# CTRL_MODULE_CORE_PAD register map
Vendor: Texas Instruments
Registers are 32-bit, access per field, reset 0x10F010F unless marked. A register's access mark holds for its fields unless they carry their own. Offsets are as the file gives them; [hi:lo] are bit positions; lines under a group give offsets from that group; {n}, {i} and the like mark numbered series; 'fields as' and 'values as' point back to an identical list.

## CTRL_MODULE_CORE_PAD (part 7 of 7)
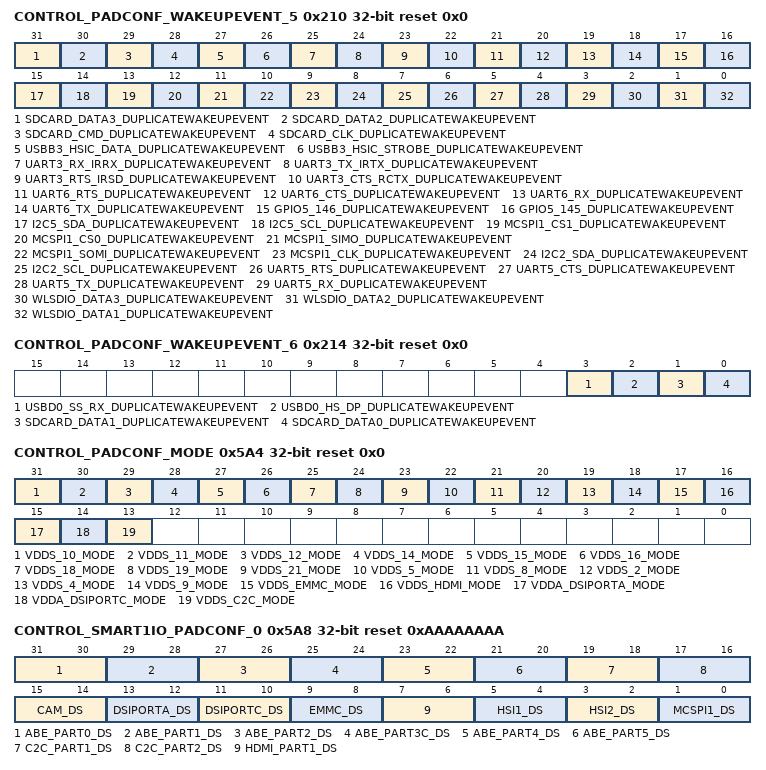
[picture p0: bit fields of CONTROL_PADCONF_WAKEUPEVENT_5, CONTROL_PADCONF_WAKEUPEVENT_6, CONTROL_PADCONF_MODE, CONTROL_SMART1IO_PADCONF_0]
0x210 CONTROL_PADCONF_WAKEUPEVENT_5 ro reset 0x0 — Access conditions. Read: unrestricted, Write: unrestricted
  [all] fields
    1=WakeUp (A wakeup event occurred); 0=No wakeup event occurred
  [31] SDCARD_DATA3_DUPLICATEWAKEUPEVENT — Wake-up event status latched in the IO for pad sdcard_data3
  [30] SDCARD_DATA2_DUPLICATEWAKEUPEVENT — Wake-up event status latched in the IO for pad sdcard_data2
  [29] SDCARD_CMD_DUPLICATEWAKEUPEVENT — Wake-up event status latched in the IO for pad sdcard_cmd
  [28] SDCARD_CLK_DUPLICATEWAKEUPEVENT — Wake-up event status latched in the IO for pad sdcard_clk
  [27] USBB3_HSIC_DATA_DUPLICATEWAKEUPEVENT — Wake-up event status latched in the IO for pad usbb3_hsic_data
  [26] USBB3_HSIC_STROBE_DUPLICATEWAKEUPEVENT — Wake-up event status latched in the IO for pad usbb3_hsic_strobe
  [25] UART3_RX_IRRX_DUPLICATEWAKEUPEVENT — Wake-up event status latched in the IO for pad uart3_rx_irrx
  [24] UART3_TX_IRTX_DUPLICATEWAKEUPEVENT — Wake-up event status latched in the IO for pad uart3_tx_irtx
  [23] UART3_RTS_IRSD_DUPLICATEWAKEUPEVENT — Wake-up event status latched in the IO for pad uart3_rts_irsd
  [22] UART3_CTS_RCTX_DUPLICATEWAKEUPEVENT — Wake-up event status latched in the IO for pad uart3_cts_rctx
  [21] UART6_RTS_DUPLICATEWAKEUPEVENT — Wake-up event status latched in the IO for pad uart6_rts
  [20] UART6_CTS_DUPLICATEWAKEUPEVENT — Wake-up event status latched in the IO for pad uart6_cts
  [19] UART6_RX_DUPLICATEWAKEUPEVENT — Wake-up event status latched in the IO for pad uart6_rx
  [18] UART6_TX_DUPLICATEWAKEUPEVENT — Wake-up event status latched in the IO for pad uart6_tx
  [17] GPIO5_146_DUPLICATEWAKEUPEVENT — Wake-up event status latched in the IO for pad gpio5_146
  [16] GPIO5_145_DUPLICATEWAKEUPEVENT — Wake-up event status latched in the IO for pad gpio5_145
  [15] I2C5_SDA_DUPLICATEWAKEUPEVENT — Wake-up event status latched in the IO for pad i2c5_sda
  [14] I2C5_SCL_DUPLICATEWAKEUPEVENT — Wake-up event status latched in the IO for pad i2c5_scl
  [13] MCSPI1_CS1_DUPLICATEWAKEUPEVENT — Wake-up event status latched in the IO for pad mcspi1_cs1
  [12] MCSPI1_CS0_DUPLICATEWAKEUPEVENT — Wake-up event status latched in the IO for pad mcspi1_cs0
  [11] MCSPI1_SIMO_DUPLICATEWAKEUPEVENT — Wake-up event status latched in the IO for pad mcspi1_simo
  [10] MCSPI1_SOMI_DUPLICATEWAKEUPEVENT — Wake-up event status latched in the IO for pad mcspi1_somi
  [9] MCSPI1_CLK_DUPLICATEWAKEUPEVENT — Wake-up event status latched in the IO for pad mcspi1_clk
  [8] I2C2_SDA_DUPLICATEWAKEUPEVENT — Wake-up event status latched in the IO for pad i2c2_sda
  [7] I2C2_SCL_DUPLICATEWAKEUPEVENT — Wake-up event status latched in the IO for pad i2c2_scl
  [6] UART5_RTS_DUPLICATEWAKEUPEVENT — Wake-up event status latched in the IO for pad uart5_rts
  [5] UART5_CTS_DUPLICATEWAKEUPEVENT — Wake-up event status latched in the IO for pad uart5_cts
  [4] UART5_TX_DUPLICATEWAKEUPEVENT — Wake-up event status latched in the IO for pad uart5_tx
  [3] UART5_RX_DUPLICATEWAKEUPEVENT — Wake-up event status latched in the IO for pad uart5_rx
  [2] WLSDIO_DATA3_DUPLICATEWAKEUPEVENT — Wake-up event status latched in the IO for pad wlsdio_data3
  [1] WLSDIO_DATA2_DUPLICATEWAKEUPEVENT — Wake-up event status latched in the IO for pad wlsdio_data2
  [0] WLSDIO_DATA1_DUPLICATEWAKEUPEVENT — Wake-up event status latched in the IO for pad wlsdio_data1
0x214 CONTROL_PADCONF_WAKEUPEVENT_6 ro reset 0x0 — Access conditions. Read: unrestricted, Write: unrestricted
  [all] fields
    values as the fields of CONTROL_PADCONF_WAKEUPEVENT_5
  [3] USBD0_SS_RX_DUPLICATEWAKEUPEVENT — Wake-up event status latched in the IO for pad usbd0_ss_rx
  [2] USBD0_HS_DP_DUPLICATEWAKEUPEVENT — Wake-up event status latched in the IO for pad usbd0_hs_dp
  [1] SDCARD_DATA1_DUPLICATEWAKEUPEVENT — Wake-up event status latched in the IO for pad sdcard_data1
  [0] SDCARD_DATA0_DUPLICATEWAKEUPEVENT — Wake-up event status latched in the IO for pad sdcard_data0
0x5A4 CONTROL_PADCONF_MODE reset 0x0 — PAD Voltage Mode control Access conditions. Read: unrestricted, Write: unrestricted
  [all] fields
    0=1V8 (VDDS = 1.8V); 1=1V2 (VDDS = 1.2V)
  [31] VDDS_10_MODE rw — PAD Voltage level control for vdds_10_mode
  [30] VDDS_11_MODE rw — PAD Voltage level control for vdds_11_mode
  [29] VDDS_12_MODE rw — PAD Voltage level control for vdds_12_mode
  [28] VDDS_14_MODE rw — PAD Voltage level control for vdds_14_mode
  [27] VDDS_15_MODE rw — PAD Voltage level control for vdds_15_mode
  [26] VDDS_16_MODE rw — PAD Voltage level control for vdds_16_mode
  [25] VDDS_18_MODE rw — PAD Voltage level control for vdds_18_mode
  [24] VDDS_19_MODE rw — PAD Voltage level control for vdds_19_mode
  [23] VDDS_21_MODE rw — PAD Voltage level control for vdds_21_mode
  [22] VDDS_5_MODE rw — PAD Voltage level control for vdds_5_mode
  [21] VDDS_8_MODE rw — PAD Voltage level control for vdds_8_mode
  [20] VDDS_2_MODE rw — PAD Voltage level control for vdds_8_mode
  [19] VDDS_4_MODE rw — PAD Voltage level control for vdds_4_mode
  [18] VDDS_9_MODE rw — PAD Voltage level control for vdds_9_mode
  [17] VDDS_EMMC_MODE rw — PAD Voltage level control for vdds_emmc_mode
  [16] VDDS_HDMI_MODE rw — PAD Voltage level control for vdds_hdmi_mode
  [15] VDDA_DSIPORTA_MODE rw — PAD Voltage level control for vdda_dsiporta_mode
  [14] VDDA_DSIPORTC_MODE rw — PAD Voltage level control for vdda_dsiporta_mode
  [13] VDDS_C2C_MODE rw — PAD Voltage level control for vdds_c2c_mode
0x5A8 CONTROL_SMART1IO_PADCONF_0 rw reset 0xAAAAAAAA — SMART1 IO control 0 Access conditions. Read: unrestricted, Write: unrestricted
  [all] fields
    0=ds0 (120 ohm); 1=ds1 (60 ohm); 3=ds3 (30 ohm); 2=ds2 (45 ohm)
  [31:30] ABE_PART0_DS — DS control for abe part0
  [29:28] ABE_PART1_DS — DS control for abe part1
  [27:26] ABE_PART2_DS — DS control for abe part2
  [25:24] ABE_PART3C_DS — DS control for abe part3 clock
  [23:22] ABE_PART4_DS — DS control for abe part4
  [21:20] ABE_PART5_DS — DS control for abe part5
  [19:18] C2C_PART1_DS — DS control for c2c part1
  [17:16] C2C_PART2_DS — DS control for c2c part2
  [15:14] CAM_DS — DS control for cam
  [13:12] DSIPORTA_DS — DS control for iporta
  [11:10] DSIPORTC_DS — DS control for iportc
  [9:8] EMMC_DS — DS control for emmc
  [7:6] HDMI_PART1_DS — DS control for hdmi part1
  [5:4] HSI1_DS — DS control for hsi1 part1
  [3:2] HSI2_DS — DS control for hsi2 part1
  [1:0] MCSPI1_DS — DS control for mcspi1
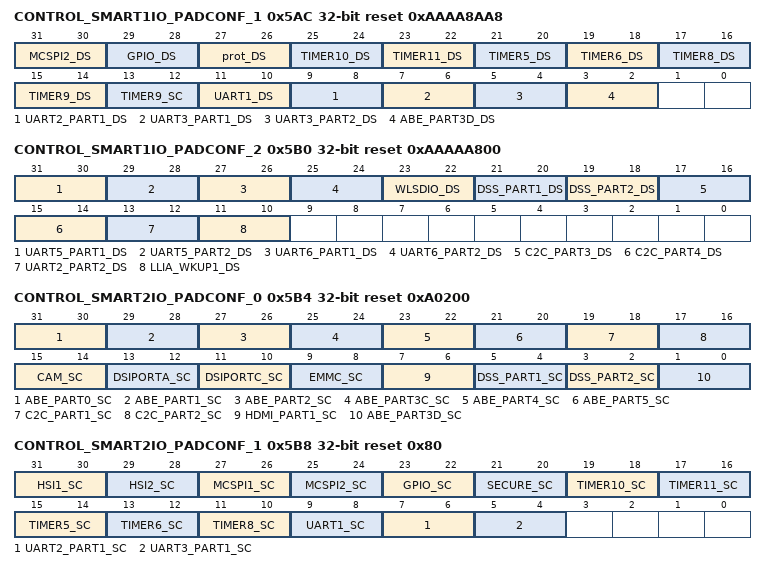
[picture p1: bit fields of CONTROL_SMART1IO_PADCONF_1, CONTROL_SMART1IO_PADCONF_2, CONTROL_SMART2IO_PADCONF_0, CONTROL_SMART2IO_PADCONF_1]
0x5AC CONTROL_SMART1IO_PADCONF_1 reset 0xAAAA8AA8 — SMART1 IO control 1 Access conditions. Read: unrestricted, Write: unrestricted
  [all] fields
    values as the fields of CONTROL_SMART1IO_PADCONF_0
  [31:30] MCSPI2_DS rw — DS control for mcspi2
  [29:28] GPIO_DS rw — DS control for gpio
  [27:26] prot_DS rw — DS control for prot
  [25:24] TIMER10_DS rw — DS control for timer10
  [23:22] TIMER11_DS rw — DS control for timer11
  [21:20] TIMER5_DS rw — DS control for timer5
  [19:18] TIMER6_DS rw — DS control for timer6
  [17:16] TIMER8_DS rw — DS control for timer8
  [15:14] TIMER9_DS rw — DS control for timer9
  [13:12] TIMER9_SC rw — DS control for timer9 sc
  [11:10] UART1_DS rw — DS control for uart1
  [9:8] UART2_PART1_DS rw — DS control for uart2 part1
  [7:6] UART3_PART1_DS rw — DS control for uart3 part1
  [5:4] UART3_PART2_DS rw — DS control for uart3 part2
  [3:2] ABE_PART3D_DS rw — DS control for abe part3 clock
0x5B0 CONTROL_SMART1IO_PADCONF_2 reset 0xAAAAA800 — SMART1 IO control 2 Access conditions. Read: unrestricted, Write: unrestricted
  [all] fields
    values as the fields of CONTROL_SMART1IO_PADCONF_0
  [31:30] UART5_PART1_DS rw — DS control for uart5 part1
  [29:28] UART5_PART2_DS rw — DS control for uart5 part2
  [27:26] UART6_PART1_DS rw — DS control for uart6 part1
  [25:24] UART6_PART2_DS rw — DS control for uart6 part2
  [23:22] WLSDIO_DS rw — DS control for wlsdio
  [21:20] DSS_PART1_DS rw — DS control for dss part1
  [19:18] DSS_PART2_DS rw — DS control for dss part1
  [17:16] C2C_PART3_DS rw — DS control for c2c part3
  [15:14] C2C_PART4_DS rw — DS control for c2c part4
  [13:12] UART2_PART2_DS rw — DS control for uart2 part2
  [11:10] LLIA_WKUP1_DS rw — DS control for llia wakeup1
0x5B4 CONTROL_SMART2IO_PADCONF_0 rw reset 0xA0200 — SMART2 IO control 0 Access conditions. Read: unrestricted, Write: unrestricted
  [31:30] ABE_PART0_SC — slew rate control for abe part0
    0=sc0 (slow); 1=sc1 (medium); 3=sc3 (not_applicable); 2=sc2 (fast)
  [29:28] ABE_PART1_SC — slew rate control for abe part1
    values as ABE_PART0_SC
  [27:26] ABE_PART2_SC — slew rate control for abe part2
    values as ABE_PART0_SC
  [25:24] ABE_PART3C_SC — slew rate control for abe part3
    values as ABE_PART0_SC
  [23:22] ABE_PART4_SC — slew rate control for abe part4
    values as ABE_PART0_SC
  [21:20] ABE_PART5_SC — slew rate control for abe part5
    values as ABE_PART0_SC
  [19:18] C2C_PART1_SC — slew rate control for c2c part1
    values as ABE_PART0_SC
  [17:16] C2C_PART2_SC — slew rate control for c2c part2
    values as ABE_PART0_SC
  [15:14] CAM_SC — slew rate control for cam
    values as ABE_PART0_SC
  [13:12] DSIPORTA_SC — slew rate control for dsiporta
    values as ABE_PART0_SC
  [11:10] DSIPORTC_SC — slew rate control for dsiportc
    values as ABE_PART0_SC
  [9:8] EMMC_SC — slew rate control for emmc
    values as ABE_PART0_SC
  [7:6] HDMI_PART1_SC — slew rate control for hdmi part1
    values as ABE_PART0_SC
  [5:4] DSS_PART1_SC — slew rate control for dss part1
    values as ABE_PART0_SC
  [3:2] DSS_PART2_SC — slew rate control for dss part2
    values as ABE_PART0_SC
  [1:0] ABE_PART3D_SC
0x5B8 CONTROL_SMART2IO_PADCONF_1 reset 0x80 — SMART2 IO control 1 Access conditions. Read: unrestricted, Write: unrestricted
  [all] fields
    values as CONTROL_SMART2IO_PADCONF_0.ABE_PART0_SC
  [31:30] HSI1_SC rw — slew rate control for hsi1 part1
  [29:28] HSI2_SC rw — slew rate control for hsi2 part1
  [27:26] MCSPI1_SC rw — slew rate control for mcspi1
  [25:24] MCSPI2_SC rw — slew rate control for mcspi2
  [23:22] GPIO_SC rw — slew rate control for gpio
  [21:20] SECURE_SC rw — slew rate control for secure
  [19:18] TIMER10_SC rw — slew rate control for timer10
  [17:16] TIMER11_SC rw — slew rate control for timer11
  [15:14] TIMER5_SC rw — slew rate control for timer5
  [13:12] TIMER6_SC rw — slew rate control for timer6
  [11:10] TIMER8_SC rw — slew rate control for timer8
  [9:8] UART1_SC rw — slew rate control for uart1
  [7:6] UART2_PART1_SC rw — slew rate control for uart2 part1
  [5:4] UART3_PART1_SC rw — slew rate control for uart3 part1
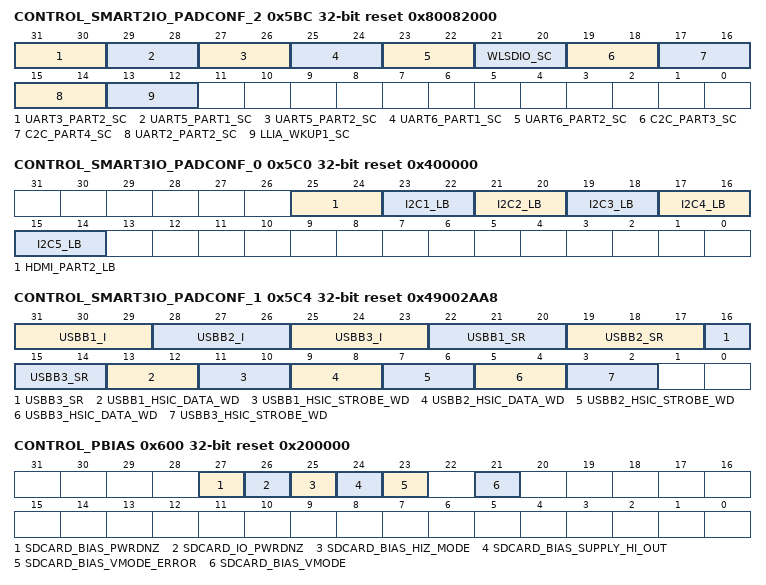
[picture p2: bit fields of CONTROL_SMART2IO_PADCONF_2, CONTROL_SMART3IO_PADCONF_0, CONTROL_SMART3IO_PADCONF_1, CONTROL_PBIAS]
0x5BC CONTROL_SMART2IO_PADCONF_2 reset 0x80082000 — SMART2 IO control 2 Access conditions. Read: unrestricted, Write: unrestricted
  [all] fields
    values as CONTROL_SMART2IO_PADCONF_0.ABE_PART0_SC
  [31:30] UART3_PART2_SC rw — slew rate control for uart3 part2
  [29:28] UART5_PART1_SC rw — slew rate control for uart5 part1
  [27:26] UART5_PART2_SC rw — slew rate control for uart5 part2
  [25:24] UART6_PART1_SC rw — slew rate control for uart6 part1
  [23:22] UART6_PART2_SC rw — slew rate control for uart6 part2
  [21:20] WLSDIO_SC rw — slew rate control for wlsdio
  [19:18] C2C_PART3_SC rw — slew rate control for c2c part3
  [17:16] C2C_PART4_SC rw — slew rate control for c2c part4
  [15:14] UART2_PART2_SC rw — slew rate control for uart2 part2
  [13:12] LLIA_WKUP1_SC rw — slew rate control for llia wakeup
0x5C0 CONTROL_SMART3IO_PADCONF_0 reset 0x400000 — SMART3 IO control 0. samrt reflex Access conditions. Read: unrestricted, Write: unrestricted
  [all] fields
    0=lb0 (Fast mode(5-15pf),High-Speed mode(5-12pf)); 1=lb1 (Fast mode(15-50pf),High-Speed mode(12-25pf)); 3=lb3 (Fast mode(N/A),High-Speed mode(50-80pf)); 2=lb2 (Fast mode(50-150pf),High-Speed mode(25-50pf))
  [25:24] HDMI_PART2_LB rw — lb (internal pull-up resistors for both Fast and High-Speed modes) for control for hdmi_part2
  [25-2n:24-2n] I2C{n}_LB rw (n=1..5) — lb (internal pull-up resistors for both Fast and High-Speed modes) for control for i2c{n}
0x5C4 CONTROL_SMART3IO_PADCONF_1 reset 0x49002AA8 — SMART3 IO control 1 Access conditions. Read: unrestricted, Write: unrestricted
  [31:29] USBB1_I rw — usbb1 HSIC Impedence control i3:i2:i0
    0=i2 (i0)
  [28:26] USBB2_I rw — usbb2 HSIC Impedence control i3:i2:i0
    0=i2 (i0)
  [25:23] USBB3_I rw — usbb3 HSIC Impedence control i3:i2:i0
    0=i2 (i0)
  [22:20] USBB1_SR rw — usbb1 HSIC Slew Rate control sr2:sr1:sr0
    0=sr1 (sr0)
  [19:17] USBB2_SR rw — usbb2 HSIC Slew Rate control sr2:sr1:sr0
    0=sr1 (sr0)
  [16:14] USBB3_SR rw — usbb3 HSIC Slew Rate control sr2:sr1:sr0
    0=sr1 (sr0)
  [13:12] USBB1_HSIC_DATA_WD rw — usbb1 HSIC DATA Weak Driver control i2:i0
    0=i0
  [11:10] USBB1_HSIC_STROBE_WD rw — usbb1 HSIC STROBE Weak Driver control i2:i0
    0=i0
  [9:8] USBB2_HSIC_DATA_WD rw — usbb2 HSIC DATA Weak Driver control i2:i0
    0=i0
  [7:6] USBB2_HSIC_STROBE_WD rw — usbb2 HSIC STROBE Weak Driver control i2:i0
    0=i0
  [5:4] USBB3_HSIC_DATA_WD rw — usbb3 HSIC DATA Weak Driver control i2:i0
    0=i0
  [3:2] USBB3_HSIC_STROBE_WD rw — usbb3 HSIC STROBE Weak Driver control i2:i0
    0=i0
0x600 CONTROL_PBIAS reset 0x200000 — PBIAS control Access conditions. Read: unrestricted, Write: unrestricted
  [27] SDCARD_BIAS_PWRDNZ rw — PWRDNZ control for SDCARD PBIAS cell
    0=Enable (This signal is used to protect SDCARD PBIAS cell when SDCARD_VDDS is not stable); 1=Disable (SW keep this bit to 1'b1 after SDCARD_VDDS stabilizing)
  [26] SDCARD_IO_PWRDNZ rw — PWRDNZ control for SDCARD I/O cell
    0=Enable (This signal is used to protect SDCARD IOs when SDCARD_VDDS is not stable); 1=Disable (SW keep this bit to 1'b1 after SDCARD_VDDS stabilizing)
  [25] SDCARD_BIAS_HIZ_MODE rw — HIZ_MODE from SDCARD PBIAS
    0=Enable (PBIAS in normal operation mode); 1=Disable (PBIAS output is in high impedence state)
  [24] SDCARD_BIAS_SUPPLY_HI_OUT ro — SUPPLY_HI_OUT from SDCARD PBIAS
    1=3V (SDCARD_VDDS = 3V); 0=1V8 (SDCARD_VDDS = 1.8V)
  [23] SDCARD_BIAS_VMODE_ERROR ro — VMODE ERROR from SDCARD PBIAS
    1=VMODE_ERROR1 (VMODE level is not same as SUPPLY_HI_OUT); 0=VMODE_ERROR0 (VMODE level is same as SUPPLY_HI_OUT)
  [21] SDCARD_BIAS_VMODE rw — VMODE control to SDCARD PBIAS. Not applicable when the pad muxing selects SDCARD. When SDCARD is selected by the pad muxing, PBIAS VMODE is directly controlled by the MMCHS IP via bit MMCHS.MMCHS_AC12[19] V1V8_SIGEN
    0=1V8 (SDCARD_VDDS = 1.8V); 1=3V (SDCARD_VDDS = 3V)
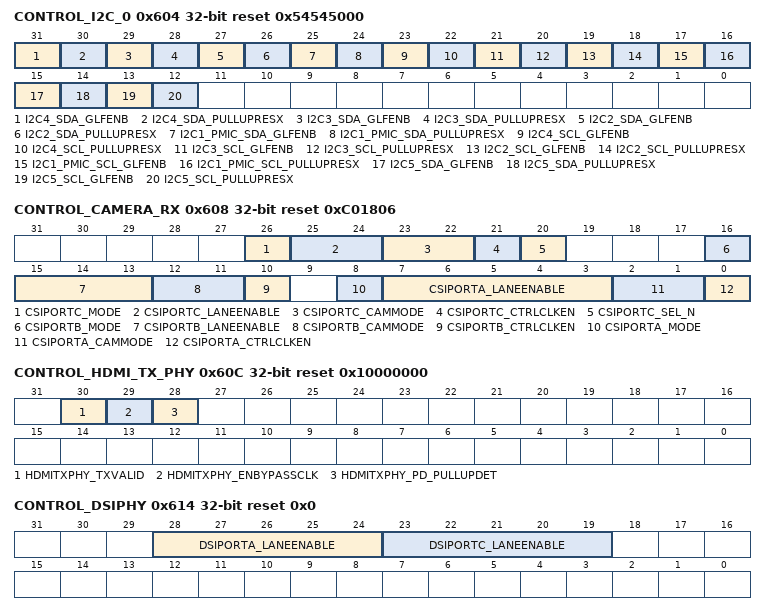
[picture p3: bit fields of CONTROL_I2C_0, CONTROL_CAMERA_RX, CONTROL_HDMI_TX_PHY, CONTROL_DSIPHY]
0x604 CONTROL_I2C_0 reset 0x54545000 — I2C pads control 0 Access conditions. Read: unrestricted, Write: unrestricted
  [31] I2C4_SDA_GLFENB rw — Active_high glitch free operation enable pin for i2c4 receiver
    0=Disable i2c4 glitch free operation; 1=Enable i2c4 glitch free operation
  [30] I2C4_SDA_PULLUPRESX rw — Active_low internal pull_up resistor enabled for i2c4
    0=Enable Internal Pull up resistor; 1=Disable Internal Pull up resisitor
  [29] I2C3_SDA_GLFENB rw — Active_high glitch free operation enable pin for i2c3 receiver
    values as I2C4_SDA_GLFENB
  [28] I2C3_SDA_PULLUPRESX rw — Active_low internal pull_up resistor enabled for i2c3
    values as I2C4_SDA_PULLUPRESX
  [27] I2C2_SDA_GLFENB rw — Active_high glitch free operation enable pin for i2c2 receiver
    values as I2C4_SDA_GLFENB
  [26] I2C2_SDA_PULLUPRESX rw — Active_low internal pull_up resistor enabled for i2c2
    values as I2C4_SDA_PULLUPRESX
  [25] I2C1_PMIC_SDA_GLFENB rw — Active_high glitch free operation enable pin for i2c1_pmic receiver
    values as I2C4_SDA_GLFENB
  [24] I2C1_PMIC_SDA_PULLUPRESX rw — Active_low internal pull_up resistor enabled for i2c1_pmic
    values as I2C4_SDA_PULLUPRESX
  [23] I2C4_SCL_GLFENB rw — Active_high glitch free operation enable pin for i2c4 receiver
    values as I2C4_SDA_GLFENB
  [22] I2C4_SCL_PULLUPRESX rw — Active_low internal pull_up resistor enabled for i2c4
    values as I2C4_SDA_PULLUPRESX
  [21] I2C3_SCL_GLFENB rw — Active_high glitch free operation enable pin for i2c3 receiver
    values as I2C4_SDA_GLFENB
  [20] I2C3_SCL_PULLUPRESX rw — Active_low internal pull_up resistor enabled for i2c3
    values as I2C4_SDA_PULLUPRESX
  [19] I2C2_SCL_GLFENB rw — Active_high glitch free operation enable pin for i2c2 receiver
    values as I2C4_SDA_GLFENB
  [18] I2C2_SCL_PULLUPRESX rw — Active_low internal pull_up resistor enabled for i2c2
    values as I2C4_SDA_PULLUPRESX
  [17] I2C1_PMIC_SCL_GLFENB rw — Active_high glitch free operation enable pin for i2c1_pmic receiver
    values as I2C4_SDA_GLFENB
  [16] I2C1_PMIC_SCL_PULLUPRESX rw — Active_low internal pull_up resistor enabled for i2c1_pmic
    values as I2C4_SDA_PULLUPRESX
  [15] I2C5_SDA_GLFENB rw — Active_high glitch free operation enable pin for i2c5 receiver
    0=Disable i2c5 glitch free operation; 1=Enable i2c5 glitch free operation
  [14] I2C5_SDA_PULLUPRESX rw — Active_low internal pull_up resistor enabled for i2c5
    values as I2C4_SDA_PULLUPRESX
  [13] I2C5_SCL_GLFENB rw — Active_high glitch free operation enable pin for i2c5 receiver
    values as I2C5_SDA_GLFENB
  [12] I2C5_SCL_PULLUPRESX rw — Active_low internal pull_up resistor enabled for i2c5
    values as I2C4_SDA_PULLUPRESX
0x608 CONTROL_CAMERA_RX reset 0xC01806 — CAMERA RX control Access conditions. Read: unrestricted, Write: unrestricted
  [26] CSIPORTC_MODE rw — portc camera MODE
  [25:24] CSIPORTC_LANEENABLE rw — portc camera Lane Enable
    0=Disable (Lane module disabled); 1=Enable (Lane module enabled)
  [23:22] CSIPORTC_CAMMODE rw — portc camera CAMMODE control
    0=DPHY (DPHY mode); 1=CCP2_Data_Strobe (Data/Strobe Transmission for mat); 3=GPI (GPI mode); 2=CCP2_Data_Clock (Data/Clock Transmission for mat)
  [21] CSIPORTC_CTRLCLKEN rw — portc cameraclock enable control. This is the internal PHY CTRLCLK driven from CSI_PHY_CTRL_FCLK.
    0=Disable for CTRLCLK; 1=Enable (Active high enable for CTRLCLK)
  [20] CSIPORTC_SEL_N rw — select port
    0=csiportc (select portc); 1=portb (select portb)
  [16] CSIPORTB_MODE rw — portb camera MODE
  [15:13] CSIPORTB_LANEENABLE rw — portb camera Lane Enable
    values as CSIPORTC_LANEENABLE
  [12:11] CSIPORTB_CAMMODE rw — portb camera CAMMODE control
    values as CSIPORTC_CAMMODE
  [10] CSIPORTB_CTRLCLKEN rw — portb camera clock enable control. This is the internal PHY CTRLCLK driven from CSI_PHY_CTRL_FCLK.
    values as CSIPORTC_CTRLCLKEN
  [8] CSIPORTA_MODE rw — porta camera MODE
  [7:3] CSIPORTA_LANEENABLE rw — porta camera Lane Enable
    values as CSIPORTC_LANEENABLE
  [2:1] CSIPORTA_CAMMODE rw — porta camera CAMMODE control
    values as CSIPORTC_CAMMODE
  [0] CSIPORTA_CTRLCLKEN rw — porta cameraclock enable control. This is the internal PHY CTRLCLK driven from CSI_PHY_CTRL_FCLK.
    values as CSIPORTC_CTRLCLKEN
0x60C CONTROL_HDMI_TX_PHY reset 0x10000000 — HDMI TX PHY control Access conditions. Read: unrestricted, Write: unrestricted
  [30] HDMITXPHY_TXVALID rw, [29] HDMITXPHY_ENBYPASSCLK rw, [28] HDMITXPHY_PD_PULLUPDET rw
0x614 CONTROL_DSIPHY reset 0x0 — DSIPHY control Access conditions. Read: unrestricted, Write: unrestricted
  [28:24] DSIPORTA_LANEENABLE rw
    values as CONTROL_CAMERA_RX.CSIPORTC_LANEENABLE
  [23:19] DSIPORTC_LANEENABLE rw
    0=Enable (Pull down enabled); 1=Disable (Pull down disabled)
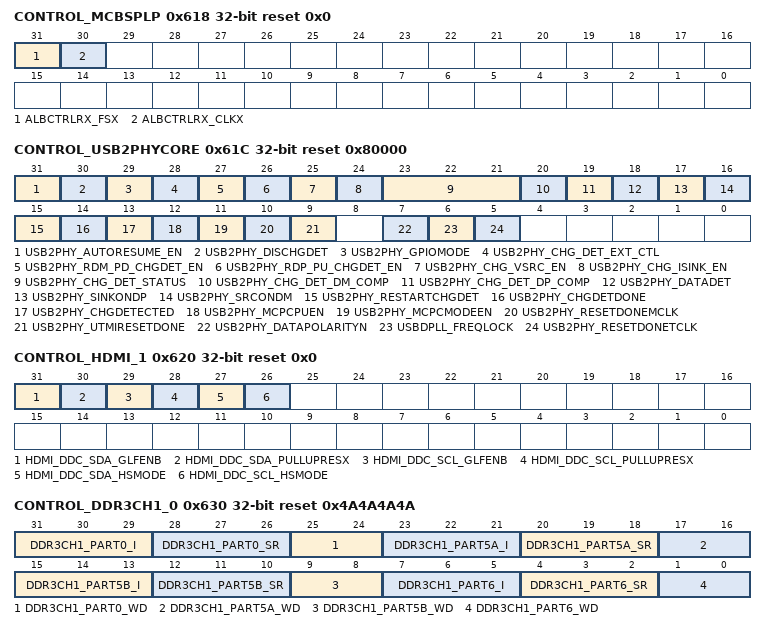
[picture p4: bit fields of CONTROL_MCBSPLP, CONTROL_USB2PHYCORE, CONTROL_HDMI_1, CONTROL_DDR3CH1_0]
0x618 CONTROL_MCBSPLP reset 0x0 — McBSPLP control Access conditions. Read: unrestricted, Write: unrestricted
  [31] ALBCTRLRX_FSX rw — Analog loop_back control for FSX
    0=PIFSR (PIFSR is used); 1=PIFSX (PIFSX is used instead of PIFSR 4pin mode)
  [30] ALBCTRLRX_CLKX rw — Analog loop_back control for CLKX
    0=PICLKR (PICLKR is used); 1=PICLKX (PICLKX is used instead of PICLKR 4pin mode)
0x61C CONTROL_USB2PHYCORE reset 0x80000 — USB2PHYCORE control Access conditions. Read: unrestricted, Write: unrestricted
  [31] USB2PHY_AUTORESUME_EN rw — Auto resume enable
    0=disable autoresume; 1=enable autoresume
  [30] USB2PHY_DISCHGDET rw — Disable charger detect
    0=Enable (charger detect function enabled); 1=Disable (charger detect function disabled)
  [29] USB2PHY_GPIOMODE rw — GPIO mode
    0=Disable (USB mode enabled); 1=Enable (GPIO mode enabled)
  [28] USB2PHY_CHG_DET_EXT_CTL rw — Charge detect external control
    0=Enable (charger detect internal state machine used); 1=Disable (charge detect statemachine is bypassed)
  [27] USB2PHY_RDM_PD_CHGDET_EN rw — DM Pull down control
    0=Disable (PD disabled); 1=Enable (PD enabled)
  [26] USB2PHY_RDP_PU_CHGDET_EN rw — DP Pull up control
    0=Disable (PU disabled); 1=Enable (PU enabled)
  [25] USB2PHY_CHG_VSRC_EN rw — VSRC enable on DP line-Host charger case
    0=disable VSRC drive on DP; 1=Enable (drives VSRC 600mV on DP line)
  [24] USB2PHY_CHG_ISINK_EN rw — ISINK enable on DM line-Host charger case
    0=disable the isink on DM; 1=enables the ISINK (100uA) on DM line
  [23:21] USB2PHY_CHG_DET_STATUS ro — Status of charger detection
    3=USB2PHY_CHG_DET_STATUS_3_r (Unknown error); 4=USB2PHY_CHG_DET_STATUS_4_r (Dedicated charger); 2=USB2PHY_CHG_DET_STATUS_2_r (PS/2); 0=USB2PHY_CHG_DET_STATUS_0_r (Wait state); 6=USB2PHY_CHG_DET_STATUS_6_r (PC); 1=USB2PHY_CHG_DET_STATUS_1_r (No contact); 7=USB2PHY_CHG_DET_STATUS_7_r (Interrupt); 5=USB2PHY_CHG_DET_STATUS_5_r (HOST charger)
  [20] USB2PHY_CHG_DET_DM_COMP ro — Output of the comparator on DM during the resistor host detect protocol
    1=Above (DM line is above 0.75V to 0.95V); 0=Below (DM line is below 0.75V to 0.95V)
  [19] USB2PHY_CHG_DET_DP_COMP ro — Output of the comparator on DP during the resistor host detect protocol
    1=Above (DP line is above 0.75V to 0.95V); 0=Below (DP line is below 0.75V to 0.95V)
  [18] USB2PHY_DATADET ro — Output of the charger detect comparator
    1=Above (DM line is above 0.25V to 0.4V); 0=Below (DM line is below 0.25V to 0.4V)
  [17] USB2PHY_SINKONDP rw — When '1' current sink is connected to DP instead of DM
    0=Default value; 1=enables the ISINK on DP instead of DM
  [16] USB2PHY_SRCONDM rw — When '1' voltage source is connected to DP instead of DM
    0=Default value; 1=enable the VSRC on DM instead of DP
  [15] USB2PHY_RESTARTCHGDET rw — restartchgdet = '1' for 1 msec cause the CD_START to reset
    0=Default value; 1=RESTART (a high pulse of 1 msec causes the charger detect to restart on negative edge of restartchgdet)
  [14] USB2PHY_CHGDETDONE ro — Status indicates that charger detection protocol is over
    1=completed (charger detection protocol is over); 0=not_completed (charger detection protocol is not over)
  [13] USB2PHY_CHGDETECTED ro — Output of the charger detection protocol
    1=detected (charger detected); 0=not_detected (charger not detected)
  [12] USB2PHY_MCPCPUEN rw — MCPC Pull up enable
    0=disable the MCPC pull up; 1=enable the 4.7K to10K pull up on receive line DP when datapolarityn is 0 and DM when datapolarityn is 1
  [11] USB2PHY_MCPCMODEEN rw — MCPC Mode enable
    0=disable MCPC mode; 1=enable MCPC mode
  [10] USB2PHY_RESETDONEMCLK ro — OCP reset status
    1=OUT_OF_RESET (OCP domain is out of reset); 0=IN_RESET (OCP domain is in reset)
  [9] USB2PHY_UTMIRESETDONE ro — UTMI FSM reset status
    1=UTMI_FSM_OUT_OF_RESET (UTMI FSMs are out of reset); 0=UTMI_FSM_INRESET (UTMI FSMs are in reset)
  [7] USB2PHY_DATAPOLARITYN rw — Data polarity
    0=Normal (DP functionality is on DP and DM funcationality is on DM); 1=INVERTED (DP functionality is on DM and DM functionality is on DP)
  [6] USBDPLL_FREQLOCK ro — Status from USB DPLL
  [5] USB2PHY_RESETDONETCLK ro — resetdonetclk status from USB2PHY
0x620 CONTROL_HDMI_1 reset 0x0 — HDMI pads control 1 Access conditions. Read: unrestricted, Write: unrestricted
  [31] HDMI_DDC_SDA_GLFENB rw — Active_high glitch free operation enable pin for hdmi_ddc_sda receiver
    0=Disable hdmi_ddc_sda glitch free operation; 1=Enable hdmi_ddc_sda glitch free operation
  [30] HDMI_DDC_SDA_PULLUPRESX rw — Active_low internal pull_up resistor enabled for hdmi_ddc_sda
    values as CONTROL_I2C_0.I2C4_SDA_PULLUPRESX
  [29] HDMI_DDC_SCL_GLFENB rw — Active_high glitch free operation enable pin for hdmi_ddc_scl receiver
    0=Disable hdmi_ddc_sc glitch free operation; 1=Enable hdmi_ddc_sc glitch free operation
  [28] HDMI_DDC_SCL_PULLUPRESX rw — Active_low internal pull_up resistor enabled for hdmi_ddc_scl
    values as CONTROL_I2C_0.I2C4_SDA_PULLUPRESX
  [27] HDMI_DDC_SDA_HSMODE rw — Active-high selection for I2C High-Speed mode
    0=Disable (I2C Standard/Fast mode); 1=Enable I2C High speed mode
  [26] HDMI_DDC_SCL_HSMODE rw — Active-high selection for I2C High-Speed mode
    values as HDMI_DDC_SDA_HSMODE
0x630 CONTROL_DDR3CH1_0 rw reset 0x4A4A4A4A — DDR3CH1 control For more information about pad group assignment and signal group parameter controls, see , Signal Integrity Parameter Controls Overview, and . Access conditions. Read: unrestricted, Write: unrestricted
  [31:29] DDR3CH1_PART0_I — Group 0 Impedence control i3:i2:i0
    6=0p73Rext (for Drv11); 1=1p33Rext (for Drv6); 7=0p67Rext (Drv12); 0=1p6Rext (for Drv5); 2=1p14Rext (for Drv7); 4=0p88Rext (for Drv9); 5=0p8Rext (for Drv10); 3=Rext (for Drv8)
  [28:26] DDR3CH1_PART0_SR — Group 0 Slew Rate control sr2:sr1:sr0
    0=Fastest (Turn_on time 125ps for Drv8); 1=Slow (Turn_on time 500ps for Drv8); 3=Slowest (Turn_on time 750ps for Drv8); 2=Fast (Turn_on time 325ps for Drv8)
  [25:24] DDR3CH1_PART0_WD — Group 0 Weak driver control wd1:wd0
    0=None (Pull logic disabled); 1=PU (pull up); 3=Keeper (Maintain the previous output value); 2=PD (pull down)
  [23:21] DDR3CH1_PART5A_I — Group 5 Impedence control i3:i2:i0
    values as DDR3CH1_PART0_I
  [20:18] DDR3CH1_PART5A_SR — Group 5 Slew Rate control sr2:sr1:sr0
    values as DDR3CH1_PART0_SR
  [17:16] DDR3CH1_PART5A_WD — Group 5 Weak driver control wd1:wd0
    values as DDR3CH1_PART0_WD
  [15:13] DDR3CH1_PART5B_I — Group 6 Impedence control i3:i2:i0
    values as DDR3CH1_PART0_I
  [12:10] DDR3CH1_PART5B_SR — Group 6 Slew Rate control sr2:sr1:sr0
    values as DDR3CH1_PART0_SR
  [9:8] DDR3CH1_PART5B_WD — Group 6 Weak driver control wd1:wd0
    values as DDR3CH1_PART0_WD
  [7:5] DDR3CH1_PART6_I — Group 6 Impedence control i3:i2:i0
    values as DDR3CH1_PART0_I
  [4:2] DDR3CH1_PART6_SR — Group 6 Slew Rate control sr2:sr1:sr0
    values as DDR3CH1_PART0_SR
  [1:0] DDR3CH1_PART6_WD — Group 6 Weak driver control wd1:wd0
    values as DDR3CH1_PART0_WD
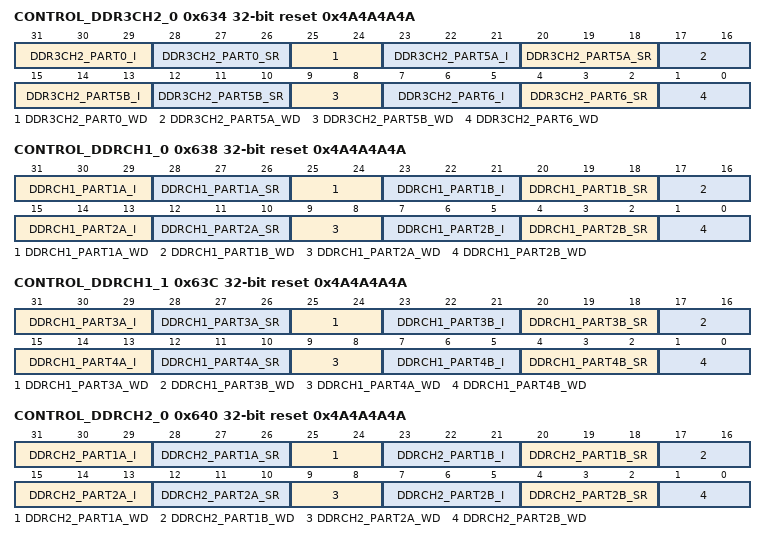
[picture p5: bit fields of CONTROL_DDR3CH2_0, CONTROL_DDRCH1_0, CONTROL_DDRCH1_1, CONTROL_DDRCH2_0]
0x634 CONTROL_DDR3CH2_0 rw reset 0x4A4A4A4A — DDR3CH2 control For more information about pad group assignment and signal group parameter controls, see , Signal Integrity Parameter Controls Overview, and . Access conditions. Read: unrestricted, Write: unrestricted
  [31:29] DDR3CH2_PART0_I — Group 0 Impedence control i3:i2:i0
    values as CONTROL_DDR3CH1_0.DDR3CH1_PART0_I
  [28:26] DDR3CH2_PART0_SR — Group 0 Slew Rate control sr2:sr1:sr0
    values as CONTROL_DDR3CH1_0.DDR3CH1_PART0_SR
  [25:24] DDR3CH2_PART0_WD — Group 0 Weak driver control wd1:wd0
    values as CONTROL_DDR3CH1_0.DDR3CH1_PART0_WD
  [23:21] DDR3CH2_PART5A_I — Group 5 Impedence control i3:i2:i0
    values as CONTROL_DDR3CH1_0.DDR3CH1_PART0_I
  [20:18] DDR3CH2_PART5A_SR — Group 5 Slew Rate control sr2:sr1:sr0
    values as CONTROL_DDR3CH1_0.DDR3CH1_PART0_SR
  [17:16] DDR3CH2_PART5A_WD — Group 5 Weak driver control wd1:wd0
    values as CONTROL_DDR3CH1_0.DDR3CH1_PART0_WD
  [15:13] DDR3CH2_PART5B_I — Group 6 Impedence control i3:i2:i0
    values as CONTROL_DDR3CH1_0.DDR3CH1_PART0_I
  [12:10] DDR3CH2_PART5B_SR — Group 6 Slew Rate control sr2:sr1:sr0
    values as CONTROL_DDR3CH1_0.DDR3CH1_PART0_SR
  [9:8] DDR3CH2_PART5B_WD — Group 6 Weak driver control wd1:wd0
    values as CONTROL_DDR3CH1_0.DDR3CH1_PART0_WD
  [7:5] DDR3CH2_PART6_I — Group 6 Impedence control i3:i2:i0
    values as CONTROL_DDR3CH1_0.DDR3CH1_PART0_I
  [4:2] DDR3CH2_PART6_SR — Group 6 Slew Rate control sr2:sr1:sr0
    values as CONTROL_DDR3CH1_0.DDR3CH1_PART0_SR
  [1:0] DDR3CH2_PART6_WD — Group 6 Weak driver control wd1:wd0
    values as CONTROL_DDR3CH1_0.DDR3CH1_PART0_WD
0x638 CONTROL_DDRCH1_0 rw reset 0x4A4A4A4A — DDRCH1 control 0 For more information about pad group assignment and signal group parameter controls, see , Signal Integrity Parameter Controls Overview, and . Access conditions. Read: unrestricted, Write: unrestricted
  [31:29] DDRCH1_PART1A_I — Group 1a Impedence control i3:i2:i0
    values as CONTROL_DDR3CH1_0.DDR3CH1_PART0_I
  [28:26] DDRCH1_PART1A_SR — Group 1a Slew Rate control sr2:sr1:sr0
    values as CONTROL_DDR3CH1_0.DDR3CH1_PART0_SR
  [25:24] DDRCH1_PART1A_WD — Group 1a Weak driver control wd1:wd0
    values as CONTROL_DDR3CH1_0.DDR3CH1_PART0_WD
  [23:21] DDRCH1_PART1B_I — Group 1b Impedence control i3:i2:i0
    values as CONTROL_DDR3CH1_0.DDR3CH1_PART0_I
  [20:18] DDRCH1_PART1B_SR — Group 1b Slew Rate control sr2:sr1:sr0
    values as CONTROL_DDR3CH1_0.DDR3CH1_PART0_SR
  [17:16] DDRCH1_PART1B_WD — Group 1b Weak driver control wd1:wd0
    values as CONTROL_DDR3CH1_0.DDR3CH1_PART0_WD
  [15:13] DDRCH1_PART2A_I — Group 2a Impedence control i3:i2:i0
    values as CONTROL_DDR3CH1_0.DDR3CH1_PART0_I
  [12:10] DDRCH1_PART2A_SR — Group 2a Slew Rate control sr2:sr1:sr0
    values as CONTROL_DDR3CH1_0.DDR3CH1_PART0_SR
  [9:8] DDRCH1_PART2A_WD — Group 2a Weak driver control wd1:wd0
    values as CONTROL_DDR3CH1_0.DDR3CH1_PART0_WD
  [7:5] DDRCH1_PART2B_I — Group 2b Impedence control i3:i2:i0
    values as CONTROL_DDR3CH1_0.DDR3CH1_PART0_I
  [4:2] DDRCH1_PART2B_SR — Group 2b Slew Rate control sr2:sr1:sr0
    values as CONTROL_DDR3CH1_0.DDR3CH1_PART0_SR
  [1:0] DDRCH1_PART2B_WD — Group 2b Weak driver control wd1:wd0
    values as CONTROL_DDR3CH1_0.DDR3CH1_PART0_WD
0x63C CONTROL_DDRCH1_1 rw reset 0x4A4A4A4A — DDRCH1 control 1 For more information about pad group assignment and signal group parameter controls, see , Signal Integrity Parameter Controls Overview, and . Access conditions. Read: unrestricted, Write: unrestricted
  [31:29] DDRCH1_PART3A_I — Group 3a Impedence control i3:i2:i0
    values as CONTROL_DDR3CH1_0.DDR3CH1_PART0_I
  [28:26] DDRCH1_PART3A_SR — Group 3a Slew Rate control sr2:sr1:sr0
    values as CONTROL_DDR3CH1_0.DDR3CH1_PART0_SR
  [25:24] DDRCH1_PART3A_WD — Group 3a Weak driver control wd1:wd0
    values as CONTROL_DDR3CH1_0.DDR3CH1_PART0_WD
  [23:21] DDRCH1_PART3B_I — Group 3b Impedence control i3:i2:i0
    values as CONTROL_DDR3CH1_0.DDR3CH1_PART0_I
  [20:18] DDRCH1_PART3B_SR — Group 3b Slew Rate control sr2:sr1:sr0
    values as CONTROL_DDR3CH1_0.DDR3CH1_PART0_SR
  [17:16] DDRCH1_PART3B_WD — Group 3b Weak driver control wd1:wd0
    values as CONTROL_DDR3CH1_0.DDR3CH1_PART0_WD
  [15:13] DDRCH1_PART4A_I — Group 4a Impedence control i3:i2:i0
    values as CONTROL_DDR3CH1_0.DDR3CH1_PART0_I
  [12:10] DDRCH1_PART4A_SR — Group 4a Slew Rate control sr2:sr1:sr0
    values as CONTROL_DDR3CH1_0.DDR3CH1_PART0_SR
  [9:8] DDRCH1_PART4A_WD — Group 4a Weak driver control wd1:wd0
    values as CONTROL_DDR3CH1_0.DDR3CH1_PART0_WD
  [7:5] DDRCH1_PART4B_I — Group 4b Impedence control i3:i2:i0
    values as CONTROL_DDR3CH1_0.DDR3CH1_PART0_I
  [4:2] DDRCH1_PART4B_SR — Group 4b Slew Rate control sr2:sr1:sr0
    values as CONTROL_DDR3CH1_0.DDR3CH1_PART0_SR
  [1:0] DDRCH1_PART4B_WD — Group 4b Weak driver control wd1:wd0
    values as CONTROL_DDR3CH1_0.DDR3CH1_PART0_WD
0x640 CONTROL_DDRCH2_0 rw reset 0x4A4A4A4A — DDRCH2 control 0 For more information about pad group assignment and signal group parameter controls, see , Signal Integrity Parameter Controls Overview, and . Access conditions. Read: unrestricted, Write: unrestricted
  [31:29] DDRCH2_PART1A_I — Group 1a Impedence control i3:i2:i0
    values as CONTROL_DDR3CH1_0.DDR3CH1_PART0_I
  [28:26] DDRCH2_PART1A_SR — Group 1a Slew Rate control sr2:sr1:sr0
    values as CONTROL_DDR3CH1_0.DDR3CH1_PART0_SR
  [25:24] DDRCH2_PART1A_WD — Group 1a Weak driver control wd1:wd0
    values as CONTROL_DDR3CH1_0.DDR3CH1_PART0_WD
  [23:21] DDRCH2_PART1B_I — Group 1b Impedence control i3:i2:i0
    values as CONTROL_DDR3CH1_0.DDR3CH1_PART0_I
  [20:18] DDRCH2_PART1B_SR — Group 1b Slew Rate control sr2:sr1:sr0
    values as CONTROL_DDR3CH1_0.DDR3CH1_PART0_SR
  [17:16] DDRCH2_PART1B_WD — Group 1b Weak driver control wd1:wd0
    values as CONTROL_DDR3CH1_0.DDR3CH1_PART0_WD
  [15:13] DDRCH2_PART2A_I — Group 2a Impedence control i3:i2:i0
    values as CONTROL_DDR3CH1_0.DDR3CH1_PART0_I
  [12:10] DDRCH2_PART2A_SR — Group 2a Slew Rate control sr2:sr1:sr0
    values as CONTROL_DDR3CH1_0.DDR3CH1_PART0_SR
  [9:8] DDRCH2_PART2A_WD — Group 2a Weak driver control wd1:wd0
    values as CONTROL_DDR3CH1_0.DDR3CH1_PART0_WD
  [7:5] DDRCH2_PART2B_I — Group 2b Impedence control i3:i2:i0
    values as CONTROL_DDR3CH1_0.DDR3CH1_PART0_I
  [4:2] DDRCH2_PART2B_SR — Group 2b Slew Rate control sr2:sr1:sr0
    values as CONTROL_DDR3CH1_0.DDR3CH1_PART0_SR
  [1:0] DDRCH2_PART2B_WD — Group 2b Weak driver control wd1:wd0
    values as CONTROL_DDR3CH1_0.DDR3CH1_PART0_WD
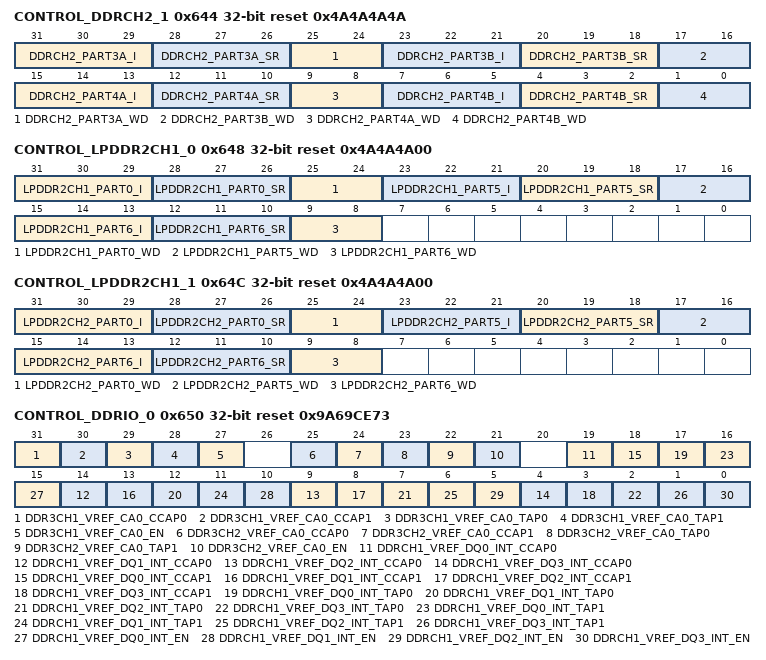
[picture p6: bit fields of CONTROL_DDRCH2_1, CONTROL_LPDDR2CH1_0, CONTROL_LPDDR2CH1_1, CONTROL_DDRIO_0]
0x644 CONTROL_DDRCH2_1 rw reset 0x4A4A4A4A — DDRCH2 control 1 For more information about pad group assignment and signal group parameter controls, see , Signal Integrity Parameter Controls Overview, and . Access conditions. Read: unrestricted, Write: unrestricted
  [31:29] DDRCH2_PART3A_I — Group 3a Impedence control i3:i2:i0
    values as CONTROL_DDR3CH1_0.DDR3CH1_PART0_I
  [28:26] DDRCH2_PART3A_SR — Group 3a Slew Rate control sr2:sr1:sr0
    values as CONTROL_DDR3CH1_0.DDR3CH1_PART0_SR
  [25:24] DDRCH2_PART3A_WD — Group 3a Weak driver control wd1:wd0
    values as CONTROL_DDR3CH1_0.DDR3CH1_PART0_WD
  [23:21] DDRCH2_PART3B_I — Group 3b Impedence control i3:i2:i0
    values as CONTROL_DDR3CH1_0.DDR3CH1_PART0_I
  [20:18] DDRCH2_PART3B_SR — Group 3b Slew Rate control sr2:sr1:sr0
    values as CONTROL_DDR3CH1_0.DDR3CH1_PART0_SR
  [17:16] DDRCH2_PART3B_WD — Group 3b Weak driver control wd1:wd0
    values as CONTROL_DDR3CH1_0.DDR3CH1_PART0_WD
  [15:13] DDRCH2_PART4A_I — Group 4a Impedence control i3:i2:i0
    values as CONTROL_DDR3CH1_0.DDR3CH1_PART0_I
  [12:10] DDRCH2_PART4A_SR — Group 4a Slew Rate control sr2:sr1:sr0
    values as CONTROL_DDR3CH1_0.DDR3CH1_PART0_SR
  [9:8] DDRCH2_PART4A_WD — Group 4a Weak driver control wd1:wd0
    values as CONTROL_DDR3CH1_0.DDR3CH1_PART0_WD
  [7:5] DDRCH2_PART4B_I — Group 4b Impedence control i3:i2:i0
    values as CONTROL_DDR3CH1_0.DDR3CH1_PART0_I
  [4:2] DDRCH2_PART4B_SR — Group 4b Slew Rate control sr2:sr1:sr0
    values as CONTROL_DDR3CH1_0.DDR3CH1_PART0_SR
  [1:0] DDRCH2_PART4B_WD — Group 4b Weak driver control wd1:wd0
    values as CONTROL_DDR3CH1_0.DDR3CH1_PART0_WD
0x648 CONTROL_LPDDR2CH1_0 reset 0x4A4A4A00 — LPDDR2 1 IO control 0 For more information about pad group assignment and signal group parameter controls, see , Signal Integrity Parameter Controls Overview, and . Access conditions. Read: unrestricted, Write: unrestricted
  [31:29] LPDDR2CH1_PART0_I rw — Group 0 Impedence control i3:i2:i0
    values as CONTROL_DDR3CH1_0.DDR3CH1_PART0_I
  [28:26] LPDDR2CH1_PART0_SR rw — Group 0 Slew Rate control sr2:sr1:sr0
    values as CONTROL_DDR3CH1_0.DDR3CH1_PART0_SR
  [25:24] LPDDR2CH1_PART0_WD rw — Group 0 Weak driver control wd1:wd0
    values as CONTROL_DDR3CH1_0.DDR3CH1_PART0_WD
  [23:21] LPDDR2CH1_PART5_I rw — Group 5 Impedence control i3:i2:i0
    values as CONTROL_DDR3CH1_0.DDR3CH1_PART0_I
  [20:18] LPDDR2CH1_PART5_SR rw — Group 5 Slew Rate control sr2:sr1:sr0
    values as CONTROL_DDR3CH1_0.DDR3CH1_PART0_SR
  [17:16] LPDDR2CH1_PART5_WD rw — Group 5 Weak driver control wd1:wd0
    values as CONTROL_DDR3CH1_0.DDR3CH1_PART0_WD
  [15:13] LPDDR2CH1_PART6_I rw — Group 6 Impedence control i3:i2:i0
    values as CONTROL_DDR3CH1_0.DDR3CH1_PART0_I
  [12:10] LPDDR2CH1_PART6_SR rw — Group 6 Slew Rate control sr2:sr1:sr0
    values as CONTROL_DDR3CH1_0.DDR3CH1_PART0_SR
  [9:8] LPDDR2CH1_PART6_WD rw — Group 6 Weak driver control wd1:wd0
    values as CONTROL_DDR3CH1_0.DDR3CH1_PART0_WD
0x64C CONTROL_LPDDR2CH1_1 reset 0x4A4A4A00 — LPDDR2 1 IO control 1 For more information about pad group assignment and signal group parameter controls, see , Signal Integrity Parameter Controls Overview, and . Access conditions. Read: unrestricted, Write: unrestricted
  [31:29] LPDDR2CH2_PART0_I rw — Group 0 Impedence control i3:i2:i0
    values as CONTROL_DDR3CH1_0.DDR3CH1_PART0_I
  [28:26] LPDDR2CH2_PART0_SR rw — Group 0 Slew Rate control sr2:sr1:sr0
    values as CONTROL_DDR3CH1_0.DDR3CH1_PART0_SR
  [25:24] LPDDR2CH2_PART0_WD rw — Group 0 Weak driver control wd1:wd0
    values as CONTROL_DDR3CH1_0.DDR3CH1_PART0_WD
  [23:21] LPDDR2CH2_PART5_I rw — Group 5 Impedence control i3:i2:i0
    values as CONTROL_DDR3CH1_0.DDR3CH1_PART0_I
  [20:18] LPDDR2CH2_PART5_SR rw — Group 5 Slew Rate control sr2:sr1:sr0
    values as CONTROL_DDR3CH1_0.DDR3CH1_PART0_SR
  [17:16] LPDDR2CH2_PART5_WD rw — Group 5 Weak driver control wd1:wd0
    values as CONTROL_DDR3CH1_0.DDR3CH1_PART0_WD
  [15:13] LPDDR2CH2_PART6_I rw — Group 6 Impedence control i3:i2:i0
    values as CONTROL_DDR3CH1_0.DDR3CH1_PART0_I
  [12:10] LPDDR2CH2_PART6_SR rw — Group 6 Slew Rate control sr2:sr1:sr0
    values as CONTROL_DDR3CH1_0.DDR3CH1_PART0_SR
  [9:8] LPDDR2CH2_PART6_WD rw — Group 6 Weak driver control wd1:wd0
    values as CONTROL_DDR3CH1_0.DDR3CH1_PART0_WD
0x650 CONTROL_DDRIO_0 reset 0x9A69CE73 — DDR CONTROL 0 Access conditions. Read: unrestricted, Write: unrestricted
  [all] fields
    0=Disabled; 1=Enabled
  [31] DDR3CH1_VREF_CA0_CCAP0 rw — Selection for coupling cap connection
  [30] DDR3CH1_VREF_CA0_CCAP1 rw — Selection for coupling cap connection
  [29] DDR3CH1_VREF_CA0_TAP0 rw — Selection for internal reference voltage drive
  [28] DDR3CH1_VREF_CA0_TAP1 rw — Selection for internal reference voltage drive
  [27] DDR3CH1_VREF_CA0_EN rw — Enable
  [25] DDR3CH2_VREF_CA0_CCAP0 rw — Selection for coupling cap connection
  [24] DDR3CH2_VREF_CA0_CCAP1 rw — Selection for coupling cap connection
  [23] DDR3CH2_VREF_CA0_TAP0 rw — Selection for internal reference voltage drive
  [22] DDR3CH2_VREF_CA0_TAP1 rw — Selection for internal reference voltage drive
  [21] DDR3CH2_VREF_CA0_EN rw — Enable
  [19-5n] DDRCH1_VREF_DQ{n}_INT_CCAP0 rw (n=0..3) — Selection for coupling cap connection
  [18-5n] DDRCH1_VREF_DQ{n}_INT_CCAP1 rw (n=0..3) — Selection for coupling cap connection
  [17-5n] DDRCH1_VREF_DQ{n}_INT_TAP0 rw (n=0..3) — Selection for internal reference voltage drive
  [16-5n] DDRCH1_VREF_DQ{n}_INT_TAP1 rw (n=0..3) — Selection for internal reference voltage drive
  [15-5n] DDRCH1_VREF_DQ{n}_INT_EN rw (n=0..3) — Enable
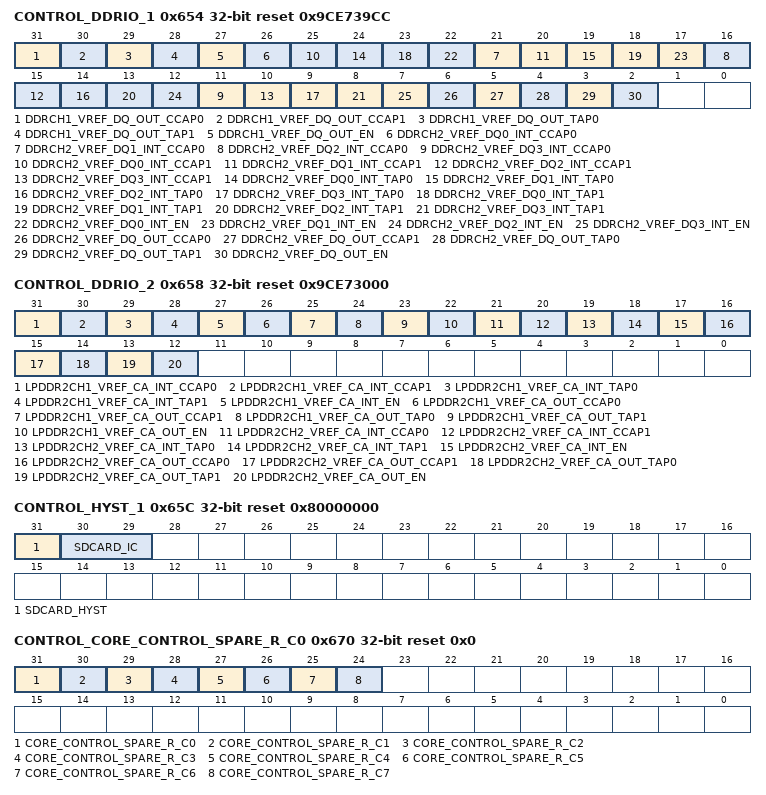
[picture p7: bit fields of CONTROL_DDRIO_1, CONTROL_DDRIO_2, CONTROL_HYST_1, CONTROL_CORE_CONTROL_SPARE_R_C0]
0x654 CONTROL_DDRIO_1 reset 0x9CE739CC — DDR CONTROL 1 Access conditions. Read: unrestricted, Write: unrestricted
  [all] fields
    0=Disabled; 1=Enabled
  [31] DDRCH1_VREF_DQ_OUT_CCAP0 rw — Selection for coupling cap connection
  [30] DDRCH1_VREF_DQ_OUT_CCAP1 rw — Selection for coupling cap connection
  [29] DDRCH1_VREF_DQ_OUT_TAP0 rw — Selection for internal reference voltage drive
  [28] DDRCH1_VREF_DQ_OUT_TAP1 rw — Selection for internal reference voltage drive
  [27] DDRCH1_VREF_DQ_OUT_EN rw — Enable
  [26-5n] DDRCH2_VREF_DQ{n}_INT_CCAP0 rw (n=0..3) — Selection for coupling cap connection
  [25-5n] DDRCH2_VREF_DQ{n}_INT_CCAP1 rw (n=0..3) — Selection for coupling cap connection
  [24-5n] DDRCH2_VREF_DQ{n}_INT_TAP0 rw (n=0..3) — Selection for internal reference voltage drive
  [23-5n] DDRCH2_VREF_DQ{n}_INT_TAP1 rw (n=0..3) — Selection for internal reference voltage drive
  [22-5n] DDRCH2_VREF_DQ{n}_INT_EN rw (n=0..3) — Enable
  [6] DDRCH2_VREF_DQ_OUT_CCAP0 rw — Selection for coupling cap connection
  [5] DDRCH2_VREF_DQ_OUT_CCAP1 rw — Selection for coupling cap connection
  [4] DDRCH2_VREF_DQ_OUT_TAP0 rw — Selection for internal reference voltage drive
  [3] DDRCH2_VREF_DQ_OUT_TAP1 rw — Selection for internal reference voltage drive
  [2] DDRCH2_VREF_DQ_OUT_EN rw — Enable
0x658 CONTROL_DDRIO_2 reset 0x9CE73000 — DDR CONTROL 2 Access conditions. Read: unrestricted, Write: unrestricted
  [all] fields
    0=Disabled; 1=Enabled
  [31] LPDDR2CH1_VREF_CA_INT_CCAP0 rw — Selection for coupling cap connection
  [30] LPDDR2CH1_VREF_CA_INT_CCAP1 rw — Selection for coupling cap connection
  [29] LPDDR2CH1_VREF_CA_INT_TAP0 rw — Selection for internal reference voltage drive
  [28] LPDDR2CH1_VREF_CA_INT_TAP1 rw — Selection for internal reference voltage drive
  [27] LPDDR2CH1_VREF_CA_INT_EN rw — Enable
  [26] LPDDR2CH1_VREF_CA_OUT_CCAP0 rw — Selection for coupling cap connection
  [25] LPDDR2CH1_VREF_CA_OUT_CCAP1 rw — Selection for coupling cap connection
  [24] LPDDR2CH1_VREF_CA_OUT_TAP0 rw — Selection for internal reference voltage drive
  [23] LPDDR2CH1_VREF_CA_OUT_TAP1 rw — Selection for internal reference voltage drive
  [22] LPDDR2CH1_VREF_CA_OUT_EN rw — Enable
  [21] LPDDR2CH2_VREF_CA_INT_CCAP0 rw — Selection for coupling cap connection
  [20] LPDDR2CH2_VREF_CA_INT_CCAP1 rw — Selection for coupling cap connection
  [19] LPDDR2CH2_VREF_CA_INT_TAP0 rw — Selection for internal reference voltage drive
  [18] LPDDR2CH2_VREF_CA_INT_TAP1 rw — Selection for internal reference voltage drive
  [17] LPDDR2CH2_VREF_CA_INT_EN rw — Enable
  [16] LPDDR2CH2_VREF_CA_OUT_CCAP0 rw — Selection for coupling cap connection
  [15] LPDDR2CH2_VREF_CA_OUT_CCAP1 rw — Selection for coupling cap connection
  [14] LPDDR2CH2_VREF_CA_OUT_TAP0 rw — Selection for internal reference voltage drive
  [13] LPDDR2CH2_VREF_CA_OUT_TAP1 rw — Selection for internal reference voltage drive
  [12] LPDDR2CH2_VREF_CA_OUT_EN rw — Enable
0x65C CONTROL_HYST_1 reset 0x80000000 — HYSTERESIS CONTROL 1 Access conditions. Read: unrestricted, Write: unrestricted
  [31] SDCARD_HYST rw — hysteresis control for sdcard
    0=Disabled; 1=Enabled
  [30:29] SDCARD_IC rw — The ic control for sdcard. Not applicable when the pad muxing selects SDCARD. When SDCARD is selected by the pad muxing, IO PAD drive strength is controlled by the MMCHS IP.In 3V signaling mode: . In 1.8V signaling mode: .
    1=ds_33 (33 Ohms Drive Strength (HS mode, 50MHz, 40pF)); 2=ds_66 (66 Ohms Drive Strength (DS mode, 25MHz, 40pF)); 0=ds_44 (44 Ohms Drive Strength (UHS - Type B, 15pF)); 1=ds_33 (33 Ohms Drive Strength (UHS - Type A, 21pF)); 2=ds_58 (58 Ohms Drive Strength ( UHS - Type C, 11pF)); 3=ds_100 (100 Ohms Drive Strength ( UHS - Type D))
0x668 CONTROL_CORE_CONTROL_SPARE_RW rw reset 0x0 — CORE control spare RW Access conditions. Read: unrestricted, Write: unrestricted
  [31:0] CORE_CONTROL_SPARE_RW — Core control spare register bits RW
0x66C CONTROL_CORE_CONTROL_SPARE_R ro reset 0x0 — CORE control spare R Access conditions. Read: unrestricted, Write: unrestricted
  [31:0] CORE_CONTROL_SPARE_R — Core control spare register bits R
0x670 CONTROL_CORE_CONTROL_SPARE_R_C0 access not given reset 0x0 — CORE control spare RC Access conditions. Read: unrestricted, Write: unrestricted
  [31-n] CORE_CONTROL_SPARE_R_C{n} (n=0..7) — Core control spare register bits RC (access RW W1toClr)
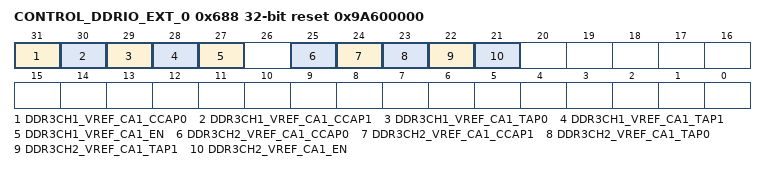
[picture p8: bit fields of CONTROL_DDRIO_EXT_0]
0x688 CONTROL_DDRIO_EXT_0 reset 0x9A600000 — DDR CONTROL EXT 0 Access conditions. Read: unrestricted, Write: unrestricted
  [all] fields
    0=Disabled; 1=Enabled
  [31] DDR3CH1_VREF_CA1_CCAP0 rw — Selection for coupling cap connection
  [30] DDR3CH1_VREF_CA1_CCAP1 rw — Selection for coupling cap connection
  [29] DDR3CH1_VREF_CA1_TAP0 rw — Selection for internal reference voltage drive
  [28] DDR3CH1_VREF_CA1_TAP1 rw — Selection for internal reference voltage drive
  [27] DDR3CH1_VREF_CA1_EN rw — Enable
  [25] DDR3CH2_VREF_CA1_CCAP0 rw — Selection for coupling cap connection
  [24] DDR3CH2_VREF_CA1_CCAP1 rw — Selection for coupling cap connection
  [23] DDR3CH2_VREF_CA1_TAP0 rw — Selection for internal reference voltage drive
  [22] DDR3CH2_VREF_CA1_TAP1 rw — Selection for internal reference voltage drive
  [21] DDR3CH2_VREF_CA1_EN rw — Enable
